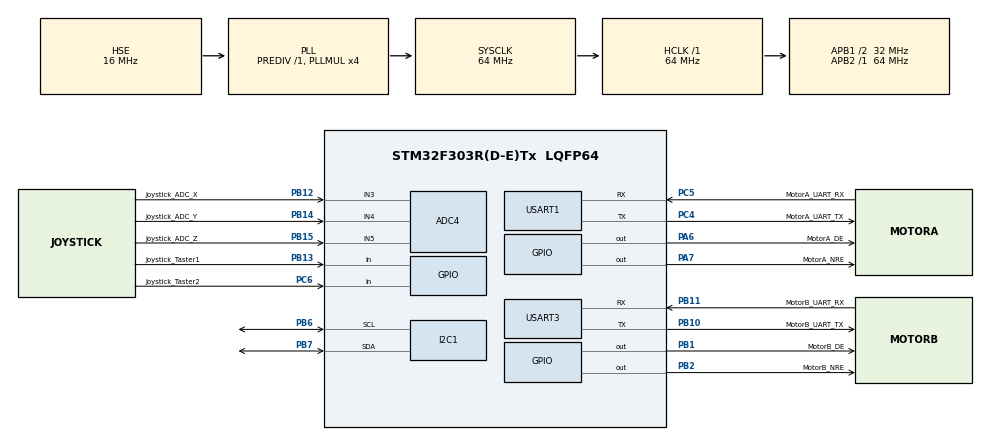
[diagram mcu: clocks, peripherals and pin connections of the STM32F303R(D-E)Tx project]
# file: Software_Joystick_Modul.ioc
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ADC4.Channel-0\#ChannelRegularConversion=ADC_CHANNEL_3
ADC4.Channel-1\#ChannelRegularConversion=ADC_CHANNEL_4
ADC4.Channel-2\#ChannelRegularConversion=ADC_CHANNEL_5
ADC4.ContinuousConvMode=ENABLE
ADC4.DMAContinuousRequests=ENABLE
ADC4.EOCSelection=ADC_EOC_SEQ_CONV
ADC4.EnableInjectedConversion=DISABLE
ADC4.NbrOfConversion=3
ADC4.NbrOfConversionFlag=1
ADC4.Offset-0\#ChannelRegularConversion=0
ADC4.Offset-1\#ChannelRegularConversion=0
ADC4.Offset-2\#ChannelRegularConversion=0
ADC4.OffsetNumber-0\#ChannelRegularConversion=ADC_OFFSET_NONE
ADC4.OffsetNumber-1\#ChannelRegularConversion=ADC_OFFSET_NONE
ADC4.OffsetNumber-2\#ChannelRegularConversion=ADC_OFFSET_NONE
ADC4.Rank-0\#ChannelRegularConversion=1
ADC4.Rank-1\#ChannelRegularConversion=2
ADC4.Rank-2\#ChannelRegularConversion=3
ADC4.SamplingTime-0\#ChannelRegularConversion=ADC_SAMPLETIME_61CYCLES_5
ADC4.SamplingTime-1\#ChannelRegularConversion=ADC_SAMPLETIME_61CYCLES_5
ADC4.SamplingTime-2\#ChannelRegularConversion=ADC_SAMPLETIME_61CYCLES_5
ADC4.SamplingTimeOPAMP-1\#ChannelRegularConversion=ADC_SAMPLETIME_61CYCLES_5
ADC4.SamplingTimeOPAMP-2\#ChannelRegularConversion=ADC_SAMPLETIME_61CYCLES_5
Dma.ADC4.0.Direction=DMA_PERIPH_TO_MEMORY
Dma.ADC4.0.Instance=DMA2_Channel2
Dma.ADC4.0.MemDataAlignment=DMA_MDATAALIGN_HALFWORD
Dma.ADC4.0.MemInc=DMA_MINC_ENABLE
Dma.ADC4.0.Mode=DMA_CIRCULAR
Dma.ADC4.0.PeriphDataAlignment=DMA_PDATAALIGN_HALFWORD
Dma.ADC4.0.PeriphInc=DMA_PINC_DISABLE
Dma.ADC4.0.Priority=DMA_PRIORITY_LOW
Dma.Request0=ADC4
Mcu.Family=STM32F3
Mcu.Name=STM32F303R(D-E)Tx
Mcu.Package=LQFP64
NVIC.DMA2_Channel2_IRQn=true\:0\:0\:false\:false\:true\:false\:true\:true
NVIC.PriorityGroup=NVIC_PRIORITYGROUP_4
NVIC.USART1_IRQn=true\:0\:0\:false\:false\:true\:true\:true\:true
NVIC.USART3_IRQn=true\:0\:0\:false\:false\:true\:true\:true\:true
PA13.Mode=Serial_Wire
PA13.Signal=SYS_JTMS-SWDIO
PA14.Mode=Serial_Wire
PA14.Signal=SYS_JTCK-SWCLK
PA6.GPIO_Label=MotorA_DE
PA6.Signal=GPIO_Output
PA7.GPIO_Label=MotorA_NRE
PA7.Signal=GPIO_Output
PB1.GPIO_Label=MotorB_DE
PB1.Signal=GPIO_Output
PB10.GPIO_Label=MotorB_UART_TX
PB10.Mode=Asynchronous
PB10.Signal=USART3_TX
PB11.GPIO_Label=MotorB_UART_RX
PB11.Mode=Asynchronous
PB11.Signal=USART3_RX
PB12.GPIO_Label=Joystick_ADC_X
PB12.Mode=IN3-Single-Ended
PB12.Signal=ADC4_IN3
PB13.GPIO_Label=Joystick_Taster1
PB13.GPIO_PuPd=GPIO_PULLUP
PB13.Signal=GPIO_Input
PB14.GPIO_Label=Joystick_ADC_Y
PB14.Mode=IN4-Single-Ended
PB14.Signal=ADC4_IN4
PB15.GPIO_Label=Joystick_ADC_Z
PB15.Mode=IN5-Single-Ended
PB15.Signal=ADC4_IN5
PB2.GPIO_Label=MotorB_NRE
PB2.Signal=GPIO_Output
PB6.Mode=I2C
PB6.Signal=I2C1_SCL
PB7.Mode=I2C
PB7.Signal=I2C1_SDA
PC4.GPIO_Label=MotorA_UART_TX
PC4.Mode=Asynchronous
PC4.Signal=USART1_TX
PC5.GPIO_Label=MotorA_UART_RX
PC5.Mode=Asynchronous
PC5.Signal=USART1_RX
PC6.GPIO_Label=Joystick_Taster2
PC6.GPIO_PuPd=GPIO_PULLUP
PC6.Signal=GPIO_Input
PF0-OSC_IN.Mode=HSE-External-Oscillator
PF0-OSC_IN.Signal=RCC_OSC_IN
PF1-OSC_OUT.Mode=HSE-External-Oscillator
PF1-OSC_OUT.Signal=RCC_OSC_OUT
ProjectManager.HeapSize=0x200
ProjectManager.StackSize=0x400
ProjectManager.TargetToolchain=STM32CubeIDE
RCC.AHBFreq_Value=64000000
RCC.APB1CLKDivider=RCC_HCLK_DIV2
RCC.APB1Freq_Value=32000000
RCC.APB1TimFreq_Value=64000000
RCC.APB2Freq_Value=64000000
RCC.APB2TimFreq_Value=64000000
RCC.CortexFreq_Value=64000000
RCC.HCLKFreq_Value=64000000
RCC.HSE_VALUE=16000000
RCC.HSI_VALUE=8000000
RCC.LSE_VALUE=32768
RCC.PLLMUL=RCC_PLL_MUL4
RCC.PLLSourceVirtual=RCC_PLLSOURCE_HSE
RCC.SYSCLKFreq_VALUE=64000000
RCC.SYSCLKSourceVirtual=RCC_SYSCLKSOURCE_PLLCLK
RCC.USBFreq_Value=64000000
USART1.VirtualMode-Asynchronous=VM_ASYNC
USART3.VirtualMode-Asynchronous=VM_ASYNC
board=custom

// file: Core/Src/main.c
/* USER CODE BEGIN Header */
/**
  ******************************************************************************
  * @file           : main.c
  * @brief          : Main program body
  ******************************************************************************
  * @attention
  *
  * Copyright (c) 2026 STMicroelectronics.
  * All rights reserved.
  *
  * This software is licensed under terms that can be found in the LICENSE file
  * in the root directory of this software component.
  * If no LICENSE file comes with this software, it is provided AS-IS.
  *
  ******************************************************************************
  */
/* USER CODE END Header */
#include "main.h"
#include "adc.h"
#include "dma.h"
#include "i2c.h"
#include "usart.h"
#include "gpio.h"

/* USER CODE BEGIN Includes */

#include "Application/communication_module.h"

/* USER CODE END Includes */

void SystemClock_Config(void);

int main(void)
{

  /* MCU Configuration--------------------------------------------------------*/

  /* Reset of all peripherals, Initializes the Flash interface and the Systick. */
  HAL_Init();

  /* Configure the system clock */
  SystemClock_Config();

  /* Initialize all configured peripherals */
  MX_GPIO_Init();
  MX_DMA_Init();
  MX_ADC4_Init();
  MX_USART1_UART_Init();
  MX_USART3_UART_Init();
  MX_I2C1_Init();
  /* USER CODE BEGIN 2 */

  if (communication_module_init() != HAL_OK)
  {
      Error_Handler();
  }

  /* USER CODE END 2 */

  /* Infinite loop */
  /* USER CODE BEGIN WHILE */
  while (1)
  {
	  communication_module_process();

    /* USER CODE END WHILE */

  }
}

void SystemClock_Config(void)
{
  RCC_OscInitTypeDef RCC_OscInitStruct = {0};
  RCC_ClkInitTypeDef RCC_ClkInitStruct = {0};
  RCC_PeriphCLKInitTypeDef PeriphClkInit = {0};

  /** Initializes the RCC Oscillators according to the specified parameters
  * in the RCC_OscInitTypeDef structure.
  */
  RCC_OscInitStruct.OscillatorType = RCC_OSCILLATORTYPE_HSI|RCC_OSCILLATORTYPE_HSE;
  RCC_OscInitStruct.HSEState = RCC_HSE_ON;
  RCC_OscInitStruct.HSIState = RCC_HSI_ON;
  RCC_OscInitStruct.HSICalibrationValue = RCC_HSICALIBRATION_DEFAULT;
  RCC_OscInitStruct.PLL.PLLState = RCC_PLL_ON;
  RCC_OscInitStruct.PLL.PLLSource = RCC_PLLSOURCE_HSE;
  RCC_OscInitStruct.PLL.PLLMUL = RCC_PLL_MUL4;
  RCC_OscInitStruct.PLL.PREDIV = RCC_PREDIV_DIV1;
  if (HAL_RCC_OscConfig(&RCC_OscInitStruct) != HAL_OK)
  {
    Error_Handler();
  }

  /** Initializes the CPU, AHB and APB buses clocks
  */
  RCC_ClkInitStruct.ClockType = RCC_CLOCKTYPE_HCLK|RCC_CLOCKTYPE_SYSCLK
                              |RCC_CLOCKTYPE_PCLK1|RCC_CLOCKTYPE_PCLK2;
  RCC_ClkInitStruct.SYSCLKSource = RCC_SYSCLKSOURCE_PLLCLK;
  RCC_ClkInitStruct.AHBCLKDivider = RCC_SYSCLK_DIV1;
  RCC_ClkInitStruct.APB1CLKDivider = RCC_HCLK_DIV2;
  RCC_ClkInitStruct.APB2CLKDivider = RCC_HCLK_DIV1;

  if (HAL_RCC_ClockConfig(&RCC_ClkInitStruct, FLASH_LATENCY_2) != HAL_OK)
  {
    Error_Handler();
  }
  PeriphClkInit.PeriphClockSelection = RCC_PERIPHCLK_USART1|RCC_PERIPHCLK_USART3
                              |RCC_PERIPHCLK_I2C1|RCC_PERIPHCLK_ADC34;
  PeriphClkInit.Usart1ClockSelection = RCC_USART1CLKSOURCE_PCLK2;
  PeriphClkInit.Usart3ClockSelection = RCC_USART3CLKSOURCE_PCLK1;
  PeriphClkInit.Adc34ClockSelection = RCC_ADC34PLLCLK_DIV1;
  PeriphClkInit.I2c1ClockSelection = RCC_I2C1CLKSOURCE_HSI;
  if (HAL_RCCEx_PeriphCLKConfig(&PeriphClkInit) != HAL_OK)
  {
    Error_Handler();
  }
}

/* USER CODE BEGIN 4 */

void HAL_UART_RxCpltCallback(
    UART_HandleTypeDef *huart)
{
    communication_uart_rx_callback(huart);
}

void HAL_UART_ErrorCallback(
    UART_HandleTypeDef *huart)
{
    communication_uart_error_callback(huart);
}

/* USER CODE END 4 */

void Error_Handler(void)
{
  __disable_irq();
  while (1)
  {
  }
}
